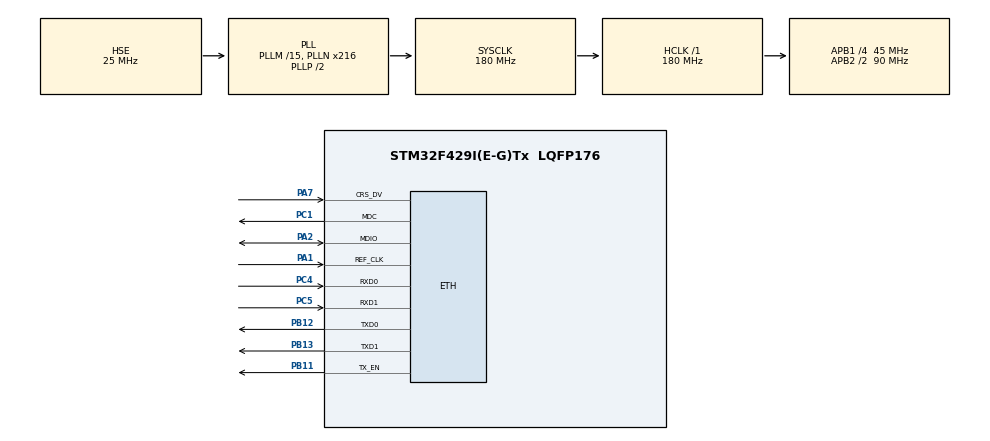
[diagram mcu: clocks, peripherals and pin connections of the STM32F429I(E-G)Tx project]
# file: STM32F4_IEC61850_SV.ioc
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ETH.MediaInterface=HAL_ETH_RMII_MODE
FREERTOS.Tasks01=defaultTask,24,512,StartDefaultTask,Default,NULL,Dynamic,NULL,NULL
LWIP.BSP.number=1
LWIP.GATEWAY_ADDRESS=192.168.000.001
LWIP.IP_ADDRESS=192.168.000.178
LWIP.LWIP_DHCP=0
LWIP.LWIP_UDP=0
LWIP.MEM_SIZE=5 * 1024
LWIP.NETMASK_ADDRESS=255.255.255.000
LWIP.TCPIP_THREAD_STACKSIZE=2 * 1024
LWIP.Version=v2.1.2_Cube
LWIP0.BSP.STBoard=false
LWIP0.BSP.api=BSP_COMPONENT_DRIVER
LWIP0.BSP.component=DP83848
LWIP0.BSP.instance=DP83848
LWIP0.BSP.name=Driver_PHY
LWIP0.BSP.semaphore=S_DP83848
LWIP0.BSP.solution=DP83848
Mcu.Family=STM32F4
Mcu.Name=STM32F429I(E-G)Tx
Mcu.Package=LQFP176
NVIC.ETH_IRQn=true\:5\:0\:false\:false\:true\:true\:false\:true\:true
NVIC.PriorityGroup=NVIC_PRIORITYGROUP_4
NVIC.TIM1_UP_TIM10_IRQn=true\:15\:0\:false\:false\:true\:false\:false\:true\:true
NVIC.TIM2_IRQn=true\:5\:0\:false\:false\:false\:true\:true\:true\:true
NVIC.TimeBase=TIM1_UP_TIM10_IRQn
NVIC.TimeBaseIP=TIM1
PA1.Mode=RMII
PA1.Signal=ETH_REF_CLK
PA13.Mode=Serial_Wire
PA13.Signal=SYS_JTMS-SWDIO
PA14.Mode=Serial_Wire
PA14.Signal=SYS_JTCK-SWCLK
PA2.Mode=RMII
PA2.Signal=ETH_MDIO
PA7.Mode=RMII
PA7.Signal=ETH_CRS_DV
PB11.Mode=RMII
PB11.Signal=ETH_TX_EN
PB12.Mode=RMII
PB12.Signal=ETH_TXD0
PB13.Mode=RMII
PB13.Signal=ETH_TXD1
PC1.Mode=RMII
PC1.Signal=ETH_MDC
PC4.Mode=RMII
PC4.Signal=ETH_RXD0
PC5.Mode=RMII
PC5.Signal=ETH_RXD1
PH0/OSC_IN.Mode=HSE-External-Oscillator
PH0/OSC_IN.Signal=RCC_OSC_IN
PH1/OSC_OUT.Mode=HSE-External-Oscillator
PH1/OSC_OUT.Signal=RCC_OSC_OUT
ProjectManager.HeapSize=0x200
ProjectManager.StackSize=0x400
ProjectManager.TargetToolchain=STM32CubeIDE
RCC.48MHZClocksFreq_Value=90000000
RCC.AHBFreq_Value=180000000
RCC.APB1CLKDivider=RCC_HCLK_DIV4
RCC.APB1Freq_Value=45000000
RCC.APB1TimFreq_Value=90000000
RCC.APB2CLKDivider=RCC_HCLK_DIV2
RCC.APB2Freq_Value=90000000
RCC.APB2TimFreq_Value=180000000
RCC.CortexFreq_Value=180000000
RCC.HCLKFreq_Value=180000000
RCC.HSE_VALUE=25000000
RCC.HSI_VALUE=16000000
RCC.LSE_VALUE=32768
RCC.PLLM=15
RCC.PLLN=216
RCC.PLLSourceVirtual=RCC_PLLSOURCE_HSE
RCC.SYSCLKFreq_VALUE=180000000
RCC.SYSCLKSource=RCC_SYSCLKSOURCE_PLLCLK
RCC.VCOOutputFreq_Value=360000000
TIM2.Period=7030
VP_FREERTOS_VS_CMSIS_V2.Mode=CMSIS_V2
VP_LWIP_VS_Enabled.Mode=Enabled
VP_SYS_VS_tim1.Mode=TIM1
VP_TIM2_VS_ClockSourceINT.Mode=Internal
board=custom

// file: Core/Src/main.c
/* USER CODE BEGIN Header */
/**
  ******************************************************************************
  * @file           : main.c
  * @brief          : Main program body
  ******************************************************************************
  * @attention
  *
  * Copyright (c) 2024 STMicroelectronics.
  * All rights reserved.
  *
  * This software is licensed under terms that can be found in the LICENSE file
  * in the root directory of this software component.
  * If no LICENSE file comes with this software, it is provided AS-IS.
  *
  ******************************************************************************
  */
/* USER CODE END Header */
#include "main.h"
#include "cmsis_os.h"
#include "lwip.h"

/* USER CODE BEGIN Includes */

#include "IEC61850_SV.h"

/* USER CODE END Includes */

TIM_HandleTypeDef htim2;

/* Definitions for defaultTask */
osThreadId_t defaultTaskHandle;
const osThreadAttr_t defaultTask_attributes = {
  .name = "defaultTask",
  .stack_size = 512 * 4,
  .priority = (osPriority_t) osPriorityNormal,
};
/* USER CODE BEGIN PV */

// IEC61850 Sampled Values task attributes
const osThreadAttr_t SVTask_attributes = {
  .name = "IEC61850_SV",
  .stack_size = 512 * 4,
  .priority = (osPriority_t) osPriorityAboveNormal,
};

/* USER CODE END PV */

void SystemClock_Config(void);
static void MX_GPIO_Init(void);
static void MX_TIM2_Init(void);
void StartDefaultTask(void *argument);

int main(void)
{

  /* MCU Configuration--------------------------------------------------------*/

  /* Reset of all peripherals, Initializes the Flash interface and the Systick. */
  HAL_Init();

  /* Configure the system clock */
  SystemClock_Config();

  /* Initialize all configured peripherals */
  MX_GPIO_Init();
  MX_TIM2_Init();

  /* Init scheduler */
  osKernelInitialize();

  /* Create the thread(s) */
  /* creation of defaultTask */
  defaultTaskHandle = osThreadNew(StartDefaultTask, NULL, &defaultTask_attributes);

  /* Start scheduler */
  osKernelStart();

  /* We should never get here as control is now taken by the scheduler */

  /* Infinite loop */
  while (1)
  {

  }
}

void SystemClock_Config(void)
{
  RCC_OscInitTypeDef RCC_OscInitStruct = {0};
  RCC_ClkInitTypeDef RCC_ClkInitStruct = {0};

  /** Configure the main internal regulator output voltage
  */
  __HAL_RCC_PWR_CLK_ENABLE();
  __HAL_PWR_VOLTAGESCALING_CONFIG(PWR_REGULATOR_VOLTAGE_SCALE1);

  /** Initializes the RCC Oscillators according to the specified parameters
  * in the RCC_OscInitTypeDef structure.
  */
  RCC_OscInitStruct.OscillatorType = RCC_OSCILLATORTYPE_HSE;
  RCC_OscInitStruct.HSEState = RCC_HSE_ON;
  RCC_OscInitStruct.PLL.PLLState = RCC_PLL_ON;
  RCC_OscInitStruct.PLL.PLLSource = RCC_PLLSOURCE_HSE;
  RCC_OscInitStruct.PLL.PLLM = 15;
  RCC_OscInitStruct.PLL.PLLN = 216;
  RCC_OscInitStruct.PLL.PLLP = RCC_PLLP_DIV2;
  RCC_OscInitStruct.PLL.PLLQ = 4;
  if (HAL_RCC_OscConfig(&RCC_OscInitStruct) != HAL_OK)
  {
    Error_Handler();
  }

  /** Activate the Over-Drive mode
  */
  if (HAL_PWREx_EnableOverDrive() != HAL_OK)
  {
    Error_Handler();
  }

  /** Initializes the CPU, AHB and APB buses clocks
  */
  RCC_ClkInitStruct.ClockType = RCC_CLOCKTYPE_HCLK|RCC_CLOCKTYPE_SYSCLK
                              |RCC_CLOCKTYPE_PCLK1|RCC_CLOCKTYPE_PCLK2;
  RCC_ClkInitStruct.SYSCLKSource = RCC_SYSCLKSOURCE_PLLCLK;
  RCC_ClkInitStruct.AHBCLKDivider = RCC_SYSCLK_DIV1;
  RCC_ClkInitStruct.APB1CLKDivider = RCC_HCLK_DIV4;
  RCC_ClkInitStruct.APB2CLKDivider = RCC_HCLK_DIV2;

  if (HAL_RCC_ClockConfig(&RCC_ClkInitStruct, FLASH_LATENCY_5) != HAL_OK)
  {
    Error_Handler();
  }
}

static void MX_TIM2_Init(void)
{

  TIM_ClockConfigTypeDef sClockSourceConfig = {0};
  TIM_MasterConfigTypeDef sMasterConfig = {0};

  htim2.Instance = TIM2;
  htim2.Init.Prescaler = 0;
  htim2.Init.CounterMode = TIM_COUNTERMODE_UP;
  htim2.Init.Period = 7030;
  htim2.Init.ClockDivision = TIM_CLOCKDIVISION_DIV1;
  htim2.Init.AutoReloadPreload = TIM_AUTORELOAD_PRELOAD_DISABLE;
  if (HAL_TIM_Base_Init(&htim2) != HAL_OK)
  {
    Error_Handler();
  }
  sClockSourceConfig.ClockSource = TIM_CLOCKSOURCE_INTERNAL;
  if (HAL_TIM_ConfigClockSource(&htim2, &sClockSourceConfig) != HAL_OK)
  {
    Error_Handler();
  }
  sMasterConfig.MasterOutputTrigger = TIM_TRGO_RESET;
  sMasterConfig.MasterSlaveMode = TIM_MASTERSLAVEMODE_DISABLE;
  if (HAL_TIMEx_MasterConfigSynchronization(&htim2, &sMasterConfig) != HAL_OK)
  {
    Error_Handler();
  }

}

static void MX_GPIO_Init(void)
{

  /* GPIO Ports Clock Enable */
  __HAL_RCC_GPIOH_CLK_ENABLE();
  __HAL_RCC_GPIOC_CLK_ENABLE();
  __HAL_RCC_GPIOA_CLK_ENABLE();
  __HAL_RCC_GPIOB_CLK_ENABLE();

}

void StartDefaultTask(void *argument)
{
  /* init code for LWIP */
  MX_LWIP_Init();
  /* USER CODE BEGIN 5 */

  // Start new task for IEC61850 SV (SV frame assembling and publishing)
  osThreadNew(IEC61850_SV_Task, NULL, &SVTask_attributes);

  /* Infinite loop */
  for(;;)
  {
    osDelay(1);
  }
  /* USER CODE END 5 */
}

void HAL_TIM_PeriodElapsedCallback(TIM_HandleTypeDef *htim)
{
  if (htim->Instance == TIM1) {
    HAL_IncTick();
  }
}

void Error_Handler(void)
{
  __disable_irq();
  while (1)
  {
  }
}
